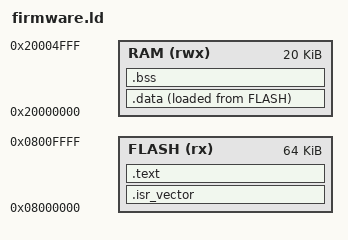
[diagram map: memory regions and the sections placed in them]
/* Minimal Cortex-M3 linker script: flash at 0x08000000, 20 KB RAM. Enough to link a real ELF. */
ENTRY(Reset_Handler)

_estack = 0x20005000;   /* top of 20 KB RAM */

MEMORY
{
    FLASH (rx)  : ORIGIN = 0x08000000, LENGTH = 64K
    RAM   (rwx) : ORIGIN = 0x20000000, LENGTH = 20K
}

SECTIONS
{
    .isr_vector : { KEEP(*(.isr_vector)) } > FLASH

    .text : {
        *(.text*)
        *(.rodata*)
    } > FLASH

    _sidata = LOADADDR(.data);
    .data : {
        _sdata = .;
        *(.data*)
        _edata = .;
    } > RAM AT> FLASH

    .bss : {
        _sbss = .;
        *(.bss*)
        *(COMMON)
        _ebss = .;
    } > RAM
}
